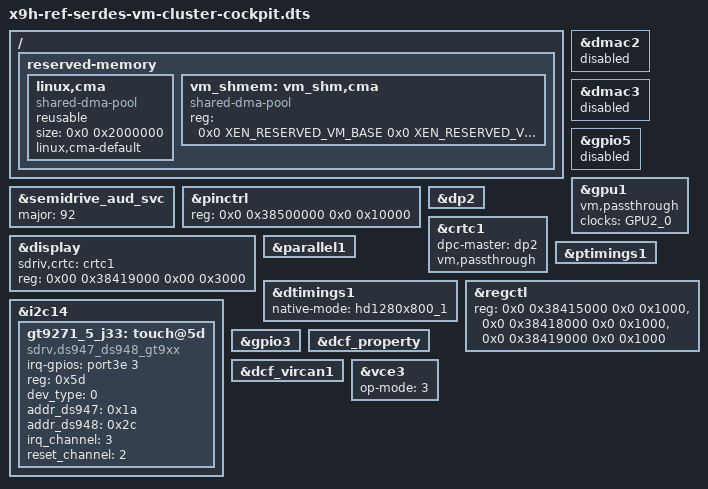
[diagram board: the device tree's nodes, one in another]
/dts-v1/;

#include "x9-vm.dtsi"
#include "display-xen.dtsi"
#include "clk-xen.dtsi"
#include "x9-clk-common-xen.dtsi"
#include "lcd-timings-xen.dtsi"
#include "x9-gpu.dtsi"
#include "x9-import.dtsi"

/ {
	reserved-memory {
		   	#address-cells = <0x2>;
		   	#size-cells = <0x2>;
		   	ranges;

			linux,cma {
			    compatible = "shared-dma-pool";
			    reusable;
			    size = <0x0 0x2000000>;
			    linux,cma-default;
			};

			vm_shmem: vm_shm,cma {
				compatible = "shared-dma-pool";
				reg = <0x0 XEN_RESERVED_VM_BASE 0x0 XEN_RESERVED_VM_SIZE>;
				status = "okay";
			};
	};

};

&dmac2 {
	status = "disabled";
};

&dmac3 {
	status = "disabled";
};
&semidrive_aud_svc {
	major = <92>;
	status = "okay";
};
&pinctrl {
	reg = <0x0 0x38500000 0x0 0x10000>;
};

&gpio5 {
	status = "disabled";
};

&gpu1 {
	status = "okay";
        vm,passthrough;
        clocks = <&GPU2_0>;
        clock-names = "gpucoreclk";
};

&display {
	sdriv,crtc = <&crtc1>;
	status = "okay";
        reg = <0x00 0x38419000 0x00 0x3000>;
};

&dp2 {
	status = "okay";
};

&crtc1 {
	dpc-master = <&dp2>;
	status = "okay";
	vm,passthrough;
};

&parallel1 {
	status = "okay";
};

&dtimings1 {
	native-mode = <&hd1280x800_1>;
};

&ptimings1 {
	status = "okay";
};

&regctl {
	reg = <0x0 0x38415000 0x0 0x1000>,
              <0x0 0x38418000 0x0 0x1000>,
              <0x0 0x38419000 0x0 0x1000>;
	reg-names = "SDRV_REG_REMAP",
			"SDRV_REG_BOOTREASON",
                        "SDRV_REG_HWID";
	status = "okay";
};

&i2c14 {
	status = "okay";

	gt9271_5_j33:touch@5d {
		compatible = "sdrv,ds947_ds948_gt9xx";
		irq-gpios = <&port3e 3 0>;	/*io83*/
		/*reset-gpios = <&ext_gpio 7 0>;		/index 7*/
		reg = <0x5d>;
		dev_type = <0>;	/* 0: main device, 1: aux device */
		addr_ds947 = <0x1a>;
		addr_ds948 = <0x2c>;
		irq_channel = <3>;
		reset_channel = <2>;
	};
};

&gpio3 {
	status = "okay";
};

&dcf_property {
	status = "okay";
};

&dcf_vircan1 {
	status = "okay";
};

&vce3 {
   /*
 	* op-mode options:
 	* bit 0: rng enable(1) or disable(0)
 	* bit 1: ce enable(1) or disable(0)
 	*/
 	op-mode = <3>;
	status = "okay";
};
